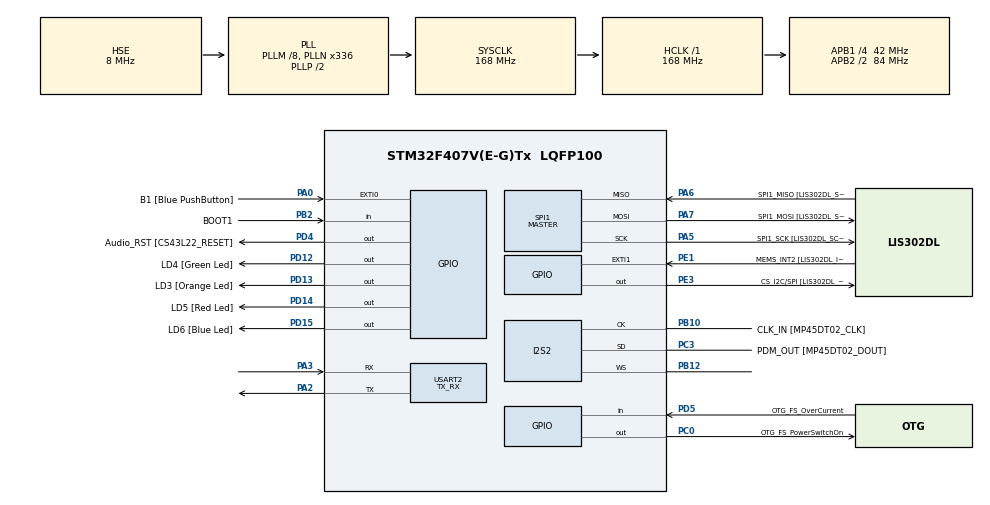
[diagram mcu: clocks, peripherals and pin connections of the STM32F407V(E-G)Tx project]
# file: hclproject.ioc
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Dma.Request0=SPI2_RX
Dma.Request1=USART2_TX
Dma.SPI2_RX.0.Direction=DMA_PERIPH_TO_MEMORY
Dma.SPI2_RX.0.FIFOMode=DMA_FIFOMODE_DISABLE
Dma.SPI2_RX.0.Instance=DMA1_Stream3
Dma.SPI2_RX.0.MemDataAlignment=DMA_MDATAALIGN_WORD
Dma.SPI2_RX.0.MemInc=DMA_MINC_ENABLE
Dma.SPI2_RX.0.Mode=DMA_CIRCULAR
Dma.SPI2_RX.0.PeriphDataAlignment=DMA_PDATAALIGN_WORD
Dma.SPI2_RX.0.PeriphInc=DMA_PINC_DISABLE
Dma.SPI2_RX.0.Priority=DMA_PRIORITY_HIGH
Dma.USART2_TX.1.Direction=DMA_MEMORY_TO_PERIPH
Dma.USART2_TX.1.FIFOMode=DMA_FIFOMODE_DISABLE
Dma.USART2_TX.1.Instance=DMA1_Stream6
Dma.USART2_TX.1.MemDataAlignment=DMA_MDATAALIGN_BYTE
Dma.USART2_TX.1.MemInc=DMA_MINC_ENABLE
Dma.USART2_TX.1.Mode=DMA_CIRCULAR
Dma.USART2_TX.1.PeriphDataAlignment=DMA_PDATAALIGN_BYTE
Dma.USART2_TX.1.PeriphInc=DMA_PINC_DISABLE
Dma.USART2_TX.1.Priority=DMA_PRIORITY_MEDIUM
I2S2.AudioFreq=I2S_AUDIOFREQ_16K
I2S2.DataFormat=I2S_DATAFORMAT_24B
I2S2.ErrorAudioFreq=-0.26 %
I2S2.FullDuplexMode=I2S_FULLDUPLEXMODE_DISABLE
I2S2.Instance=SPI$Index
I2S2.Mode=I2S_MODE_MASTER_RX
I2S2.RealAudioFreq=15.957 KHz
I2S2.VirtualMode=I2S_MODE_MASTER
Mcu.Family=STM32F4
Mcu.Name=STM32F407V(E-G)Tx
Mcu.Package=LQFP100
NVIC.DMA1_Stream3_IRQn=true\:0\:0\:false\:false\:true\:false\:true\:true
NVIC.DMA1_Stream6_IRQn=true\:0\:0\:false\:false\:true\:false\:true\:true
NVIC.PriorityGroup=NVIC_PRIORITYGROUP_0
PA0-WKUP.GPIO_Label=B1 [Blue PushButton]
PA0-WKUP.GPIO_ModeDefaultEXTI=GPIO_MODE_EVT_RISING
PA0-WKUP.GPIO_PuPd=GPIO_NOPULL
PA0-WKUP.Signal=GPXTI0
PA10.GPIO_Label=OTG_FS_ID
PA10.GPIO_Mode=GPIO_MODE_AF_PP
PA10.GPIO_PuPd=GPIO_NOPULL
PA10.GPIO_Speed=GPIO_SPEED_FREQ_LOW
PA10.Signal=USB_OTG_FS_ID
PA11.GPIO_Label=OTG_FS_DM
PA11.GPIO_Mode=GPIO_MODE_AF_PP
PA11.GPIO_PuPd=GPIO_NOPULL
PA11.GPIO_Speed=GPIO_SPEED_FREQ_LOW
PA11.Signal=USB_OTG_FS_DM
PA12.GPIO_Label=OTG_FS_DP
PA12.GPIO_Mode=GPIO_MODE_AF_PP
PA12.GPIO_PuPd=GPIO_NOPULL
PA12.GPIO_Speed=GPIO_SPEED_FREQ_LOW
PA12.Signal=USB_OTG_FS_DP
PA13.GPIO_Label=SWDIO
PA13.Mode=Serial_Wire
PA13.Signal=SYS_JTMS-SWDIO
PA14.GPIO_Label=SWCLK
PA14.Mode=Serial_Wire
PA14.Signal=SYS_JTCK-SWCLK
PA2.Mode=Asynchronous
PA2.Signal=USART2_TX
PA3.Mode=Asynchronous
PA3.Signal=USART2_RX
PA4.GPIO_Label=I2S3_WS [CS43L22_LRCK]
PA4.GPIO_Mode=GPIO_MODE_AF_PP
PA4.GPIO_PuPd=GPIO_NOPULL
PA4.GPIO_Speed=GPIO_SPEED_FREQ_LOW
PA4.Signal=I2S3_WS
PA5.GPIO_Label=SPI1_SCK [LIS302DL_SCL/SPC]
PA5.GPIO_Mode=GPIO_MODE_AF_PP
PA5.GPIO_PuPd=GPIO_NOPULL
PA5.GPIO_Speed=GPIO_SPEED_FREQ_LOW
PA5.Mode=Full_Duplex_Master
PA5.Signal=SPI1_SCK
PA6.GPIO_Label=SPI1_MISO [LIS302DL_SDO]
PA6.GPIO_Mode=GPIO_MODE_AF_PP
PA6.GPIO_PuPd=GPIO_NOPULL
PA6.GPIO_Speed=GPIO_SPEED_FREQ_LOW
PA6.Mode=Full_Duplex_Master
PA6.Signal=SPI1_MISO
PA7.GPIO_Label=SPI1_MOSI [LIS302DL_SDA/SDI/SDO]
PA7.GPIO_Mode=GPIO_MODE_AF_PP
PA7.GPIO_PuPd=GPIO_NOPULL
PA7.GPIO_Speed=GPIO_SPEED_FREQ_LOW
PA7.Mode=Full_Duplex_Master
PA7.Signal=SPI1_MOSI
PA9.GPIO_Label=VBUS_FS
PA9.GPIO_Mode=GPIO_MODE_INPUT
PA9.GPIO_PuPd=GPIO_NOPULL
PA9.Signal=USB_OTG_FS_VBUS
PB10.GPIO_Label=CLK_IN [MP45DT02_CLK]
PB10.GPIO_Mode=GPIO_MODE_AF_PP
PB10.GPIO_PuPd=GPIO_NOPULL
PB10.GPIO_Speed=GPIO_SPEED_FREQ_LOW
PB10.Mode=Half_Duplex_Master
PB10.Signal=I2S2_CK
PB12.Mode=Half_Duplex_Master
PB12.Signal=I2S2_WS
PB2.GPIO_Label=BOOT1
PB2.GPIO_Mode=GPIO_MODE_INPUT
PB2.GPIO_PuPd=GPIO_NOPULL
PB2.Signal=GPIO_Input
PB3.GPIO_Label=SWO
PB3.Signal=SYS_JTDO-SWO
PB6.GPIO_Label=Audio_SCL [CS43L22_SCL]
PB6.GPIO_Mode=GPIO_MODE_AF_OD
PB6.GPIO_Pu=GPIO_PULLUP
PB6.GPIO_PuPd=GPIO_NOPULL
PB6.GPIO_Speed=GPIO_SPEED_FREQ_LOW
PB6.Signal=I2C1_SCL
PB9.GPIO_Label=Audio_SDA [CS43L22_SDA]
PB9.GPIO_Mode=GPIO_MODE_AF_OD
PB9.GPIO_Pu=GPIO_PULLUP
PB9.GPIO_PuPd=GPIO_NOPULL
PB9.GPIO_Speed=GPIO_SPEED_FREQ_LOW
PB9.Signal=I2C1_SDA
PC0.GPIO_Label=OTG_FS_PowerSwitchOn
PC0.GPIO_PuPd=GPIO_NOPULL
PC0.GPIO_Speed=GPIO_SPEED_FREQ_LOW
PC0.PinState=GPIO_PIN_SET
PC0.Signal=GPIO_Output
PC10.GPIO_Label=I2S3_SCK [CS43L22_SCLK]
PC10.GPIO_Mode=GPIO_MODE_AF_PP
PC10.GPIO_PuPd=GPIO_NOPULL
PC10.GPIO_Speed=GPIO_SPEED_FREQ_LOW
PC10.Signal=I2S3_CK
PC12.GPIO_Label=I2S3_SD [CS43L22_SDIN]
PC12.GPIO_Mode=GPIO_MODE_AF_PP
PC12.GPIO_PuPd=GPIO_NOPULL
PC12.GPIO_Speed=GPIO_SPEED_FREQ_LOW
PC12.Signal=I2S3_SD
PC14-OSC32_IN.GPIO_Label=PC14-OSC32_IN
PC14-OSC32_IN.Mode=LSE-External-Oscillator
PC14-OSC32_IN.Signal=RCC_OSC32_IN
PC15-OSC32_OUT.GPIO_Label=PC15-OSC32_OUT
PC15-OSC32_OUT.Mode=LSE-External-Oscillator
PC15-OSC32_OUT.Signal=RCC_OSC32_OUT
PC3.GPIO_Label=PDM_OUT [MP45DT02_DOUT]
PC3.GPIO_Mode=GPIO_MODE_AF_PP
PC3.GPIO_PuPd=GPIO_NOPULL
PC3.GPIO_Speed=GPIO_SPEED_FREQ_LOW
PC3.Mode=Half_Duplex_Master
PC3.Signal=I2S2_SD
PC7.GPIO_Label=I2S3_MCK [CS43L22_MCLK]
PC7.GPIO_Mode=GPIO_MODE_AF_PP
PC7.GPIO_PuPd=GPIO_NOPULL
PC7.GPIO_Speed=GPIO_SPEED_FREQ_LOW
PC7.Signal=I2S3_MCK
PD12.GPIO_Label=LD4 [Green Led]
PD12.GPIO_PuPd=GPIO_NOPULL
PD12.GPIO_Speed=GPIO_SPEED_FREQ_LOW
PD12.Signal=GPIO_Output
PD13.GPIO_Label=LD3 [Orange Led]
PD13.GPIO_PuPd=GPIO_NOPULL
PD13.GPIO_Speed=GPIO_SPEED_FREQ_LOW
PD13.Signal=GPIO_Output
PD14.GPIO_Label=LD5 [Red Led]
PD14.GPIO_PuPd=GPIO_NOPULL
PD14.GPIO_Speed=GPIO_SPEED_FREQ_LOW
PD14.Signal=GPIO_Output
PD15.GPIO_Label=LD6 [Blue Led]
PD15.GPIO_PuPd=GPIO_NOPULL
PD15.GPIO_Speed=GPIO_SPEED_FREQ_LOW
PD15.Signal=GPIO_Output
PD4.GPIO_Label=Audio_RST [CS43L22_RESET]
PD4.GPIO_PuPd=GPIO_NOPULL
PD4.GPIO_Speed=GPIO_SPEED_FREQ_LOW
PD4.Signal=GPIO_Output
PD5.GPIO_Label=OTG_FS_OverCurrent
PD5.GPIO_Mode=GPIO_MODE_INPUT
PD5.GPIO_PuPd=GPIO_NOPULL
PD5.Signal=GPIO_Input
PE1.GPIO_Label=MEMS_INT2 [LIS302DL_INT2]
PE1.GPIO_ModeDefaultEXTI=GPIO_MODE_EVT_RISING
PE1.GPIO_PuPd=GPIO_NOPULL
PE1.Signal=GPXTI1
PE3.GPIO_Label=CS_I2C/SPI [LIS302DL_CS_I2C/SPI]
PE3.GPIO_PuPd=GPIO_NOPULL
PE3.GPIO_Speed=GPIO_SPEED_FREQ_LOW
PE3.Signal=GPIO_Output
PH0-OSC_IN.GPIO_Label=PH0-OSC_IN
PH0-OSC_IN.Mode=HSE-External-Oscillator
PH0-OSC_IN.Signal=RCC_OSC_IN
PH1-OSC_OUT.GPIO_Label=PH1-OSC_OUT
PH1-OSC_OUT.Mode=HSE-External-Oscillator
PH1-OSC_OUT.Signal=RCC_OSC_OUT
ProjectManager.HeapSize=0x200
ProjectManager.StackSize=0x400
ProjectManager.TargetToolchain=STM32CubeIDE
RCC.48MHZClocksFreq_Value=48000000
RCC.AHBFreq_Value=168000000
RCC.APB1CLKDivider=RCC_HCLK_DIV4
RCC.APB1Freq_Value=42000000
RCC.APB1TimFreq_Value=84000000
RCC.APB2CLKDivider=RCC_HCLK_DIV2
RCC.APB2Freq_Value=84000000
RCC.APB2TimFreq_Value=168000000
RCC.CortexFreq_Value=168000000
RCC.HCLKFreq_Value=168000000
RCC.HSE_VALUE=8000000
RCC.HSI_VALUE=16000000
RCC.PLLM=8
RCC.PLLN=336
RCC.PLLQ=7
RCC.PLLSourceVirtual=RCC_PLLSOURCE_HSE
RCC.SYSCLKFreq_VALUE=168000000
RCC.SYSCLKSource=RCC_SYSCLKSOURCE_PLLCLK
RCC.VCOOutputFreq_Value=336000000
SPI1.BaudRatePrescaler-Full_Duplex_Master=SPI_BAUDRATEPRESCALER_2
SPI1.CalculateBaudRate-Full_Duplex_Master=42.0 MBits/s
SPI1.Direction=SPI_DIRECTION_2LINES
SPI1.Mode=SPI_MODE_MASTER
SPI1.Mode-Full_Duplex_Master=SPI_MODE_MASTER
SPI1.VirtualType=VM_MASTER
USART2.Mode=MODE_TX_RX
USART2.VirtualMode=VM_ASYNC
board=STM32F407G-DISC1

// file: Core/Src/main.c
#include "main.h"
#include "dma.h"
#include "i2s.h"
#include "spi.h"
#include "usart.h"
#include "gpio.h"
#include "arm_math.h"
#include <stdio.h>
#include <string.h>

#define BUFFER_SIZE 1024
#define FFT_SIZE 1024
#define GAIN 2500
#define FILTER_TAP_NUM 32
#define FFT_SCALE_FACTOR (2.0f/FFT_SIZE)

#define MIN_FREQ 20
#define MAX_FREQ 8000
#define SAMPLING_RATE 8000.0f

//Calibration
#define CALIBRATION_TIME 10000
static float32_t calibration_sum = 0.0f;
static uint32_t calibration_samples = 0;
int calibrated = 0;
float32_t prev_average_magnitude = 0;

char temp[64];
// Add these at the top
#define VOCAL_START_BIN 7   // 50Hz (7*7.8Hz = 54.6Hz)
#define VOCAL_END_BIN 39    // 300Hz (39*7.8Hz = 304.2Hz)
#define BIN_GROUP_SIZE 3
#define SPIKE_THRESHOLD 4   // Adjust based on the room noise
uint8_t spike_counter = 0;
#define NO_OF_SPIKES 3

//Alert transmission
volatile uint8_t alert_pending = 0;
#define UART_FLUSH_DELAY 20

int32_t i2s_rx_buffer[2][BUFFER_SIZE];
static float32_t fft_input[FFT_SIZE] __attribute__((aligned(4)));
static float32_t fft_output[FFT_SIZE] __attribute__((aligned(4)));
static float32_t mag_output[FFT_SIZE / 2] __attribute__((aligned(4)));

volatile uint8_t active_buffer = 0;
volatile uint8_t fft_ready = 0;

// Optimized bandpass filter coefficients
const float32_t bp_filter[FILTER_TAP_NUM] = {
    -0.001747f, -0.003912f, -0.004215f, 0.000000f, 0.009645f,
    0.017835f, 0.011983f, -0.015430f, -0.042257f, -0.042351f,
    0.000000f, 0.063517f, 0.098550f, 0.063517f, 0.000000f,
    -0.042351f, -0.042257f, -0.015430f, 0.011983f, 0.017835f,
    0.009645f, 0.000000f, -0.004215f, -0.003912f, -0.001747f
};

float32_t hanning_window[FFT_SIZE];
float32_t fir_state[FFT_SIZE + FILTER_TAP_NUM - 1];
arm_rfft_fast_instance_f32 fft_instance;
arm_fir_instance_f32 fir_instance;

void SystemClock_Config(void);

// DMA Callbacks
void HAL_I2S_RxHalfCpltCallback(I2S_HandleTypeDef *hi2s) {
    active_buffer = 0;
    fft_ready = 1;
}

void HAL_I2S_RxCpltCallback(I2S_HandleTypeDef *hi2s) {
    active_buffer = 1;
    fft_ready = 1;
}

void init_filters() {
    arm_fir_init_f32(&fir_instance, FILTER_TAP_NUM, bp_filter, fir_state, FFT_SIZE);
}

void bandpass_filter(float32_t *input, float32_t *output) {
    arm_fir_f32(&fir_instance, input, output, FFT_SIZE);
}

void send_frequency_data(float* mag_output) {
    const int start_bin = (int)(MIN_FREQ * FFT_SIZE / SAMPLING_RATE);
    const int end_bin = (int)(MAX_FREQ * FFT_SIZE / SAMPLING_RATE);
    char buffer[1024];
    int offset = 0;

    // Skip bin 0 if it's below the desired frequency range
    for (int i = (start_bin > 0 ? start_bin : 1); i <= end_bin; i++) {
        float freq = i * (SAMPLING_RATE / FFT_SIZE);  // 125Hz per bin
        float mag = mag_output[i];
        offset += snprintf(buffer + offset, sizeof(buffer) - offset,
                           "%.1fhz:%.2f ", freq, mag);
        if (offset >= sizeof(buffer) - 20) break; // Prevent overflow
    }

    if (offset > 0) {
        buffer[offset-1] = '\r'; // Replace last space
        buffer[offset] = '\n';
        HAL_UART_Transmit(&huart2, (uint8_t*)buffer, offset+1, 100);
    }
}

int main(void) {
    HAL_Init();
    SystemClock_Config();
    MX_GPIO_Init();
    MX_DMA_Init();
    MX_SPI1_Init();
    MX_I2S2_Init();
    MX_USART2_UART_Init();
    __HAL_UART_FLUSH_DRREGISTER(&huart2);

    // FFT initialization
    if (arm_rfft_fast_init_1024_f32(&fft_instance) != ARM_MATH_SUCCESS) {
        char debug_buf[50];
        sprintf(debug_buf, "FFT Init Failed!\r\n");
        HAL_UART_Transmit(&huart2, (uint8_t*)debug_buf, strlen(debug_buf), 100);
        while(1);
    }
    init_filters();
    HAL_I2S_Receive_DMA(&hi2s2, (uint16_t*)i2s_rx_buffer, BUFFER_SIZE * 2);

    while(1) {
        if(fft_ready) {
            fft_ready = 0;
            int32_t *processing_buffer = i2s_rx_buffer[active_buffer];

            // DC offset calculation
            int32_t dc_offset = 0;
            for(int i=0; i<FFT_SIZE; i++) {
                dc_offset += (processing_buffer[i] << 8) >> 8;
            }
            dc_offset /= FFT_SIZE;

            // Convert to float
            for(int i=0; i<FFT_SIZE; i++) {
                int32_t pcm_data = ((processing_buffer[i] << 8) >> 8) - dc_offset;
                pcm_data *= GAIN;
                fft_input[i] = (float32_t)pcm_data / 8388608.0f;
            }

            // Filtering and windowing
            float32_t filtered_output[FFT_SIZE];
            bandpass_filter(fft_input, filtered_output);
            arm_hanning_f32(hanning_window, FFT_SIZE);
            for(int i=0; i<FFT_SIZE; i++) {
                fft_input[i] = filtered_output[i] * hanning_window[i];
            }

            // FFT processing
            arm_rfft_fast_f32(&fft_instance, fft_input, fft_output, 0);
            arm_cmplx_mag_f32(fft_output, mag_output, FFT_SIZE/2);

            for(int i=0; i<FFT_SIZE/2; i++) {
                mag_output[i] *= FFT_SCALE_FACTOR * GAIN;
            }

            send_frequency_data(mag_output);

            if(!calibrated) {
                if(HAL_GetTick() <= CALIBRATION_TIME) {
                    // Store baseline for each bin group
                    for(int i=VOCAL_START_BIN; i<VOCAL_END_BIN; i+=BIN_GROUP_SIZE) {
                        float group_sum = 0;
                        for(int j=0; j<BIN_GROUP_SIZE; j++){
                            if(i+j >= FFT_SIZE/2) break;
                            group_sum += mag_output[i+j];
                        }
                        calibration_sum += group_sum/BIN_GROUP_SIZE;
                        calibration_samples++;
                    }
                }
                else {
                    // Calculate average per bin group
                    prev_average_magnitude = calibration_sum / calibration_samples;
                    calibrated = 1;

                    char cal_msg[64];
                    snprintf(cal_msg, sizeof(cal_msg), "CALIBRATED:%.2f\r\n", prev_average_magnitude);

                    HAL_UART_Transmit(&huart2, (uint8_t*)cal_msg, strlen(cal_msg), 100);
                }
            }
            else {
                float current_spike_sum = 0;
                uint8_t spiked_groups = 0;

                // Check each bin group in vocal range
                for(int i=VOCAL_START_BIN; i<VOCAL_END_BIN; i+=BIN_GROUP_SIZE) {
                    float group_sum = 0;

                    // Calculate current group average
                    for(int j=0; j<BIN_GROUP_SIZE; j++){
                        if(i+j >= FFT_SIZE/2) break;
                        group_sum += mag_output[i+j];
                    }
                    float group_avg = group_sum/BIN_GROUP_SIZE;

                    // Detect spikes in this bin group
                    if(group_avg > (prev_average_magnitude * SPIKE_THRESHOLD)) {
                        spiked_groups++;
                        current_spike_sum += group_avg;
                    }
                }

                // If at least 2 bin groups spiked
                if(spiked_groups >= 2) {
                    spike_counter++;

                    // Require 3 consecutive detections
                    if(spike_counter >= NO_OF_SPIKES) {
                        float current_avg = current_spike_sum/spiked_groups;
                        char alert_msg[64];
                        snprintf(alert_msg, sizeof(alert_msg),"ALERT:%.2f/%.2f\r\n",
                                current_avg, prev_average_magnitude);
                        HAL_UART_Transmit(&huart2, (uint8_t*)alert_msg, strlen(alert_msg), 100);
                        spike_counter = 0;
                    }
                }
                else {
                    // Decay spike counter
                    spike_counter = spike_counter > 0 ? spike_counter-1 : 0;
                }

                if(spike_counter == 0) {
                    prev_average_magnitude = 0.95f * prev_average_magnitude + 0.05f * current_spike_sum;
                }
            }

        }
        HAL_Delay(1);
    }
}
void SystemClock_Config(void)
{
  RCC_OscInitTypeDef RCC_OscInitStruct = {0};
  RCC_ClkInitTypeDef RCC_ClkInitStruct = {0};

  /** Configure the main internal regulator output voltage
  */
  __HAL_RCC_PWR_CLK_ENABLE();
  __HAL_PWR_VOLTAGESCALING_CONFIG(PWR_REGULATOR_VOLTAGE_SCALE1);

  /** Initializes the RCC Oscillators according to the specified parameters
  * in the RCC_OscInitTypeDef structure.
  */
  RCC_OscInitStruct.OscillatorType = RCC_OSCILLATORTYPE_HSE;
  RCC_OscInitStruct.HSEState = RCC_HSE_ON;
  RCC_OscInitStruct.PLL.PLLState = RCC_PLL_ON;
  RCC_OscInitStruct.PLL.PLLSource = RCC_PLLSOURCE_HSE;
  RCC_OscInitStruct.PLL.PLLM = 8;
  RCC_OscInitStruct.PLL.PLLN = 336;
  RCC_OscInitStruct.PLL.PLLP = RCC_PLLP_DIV2;
  RCC_OscInitStruct.PLL.PLLQ = 7;
  if (HAL_RCC_OscConfig(&RCC_OscInitStruct) != HAL_OK)
  {
    Error_Handler();
  }

  /** Initializes the CPU, AHB and APB buses clocks
  */
  RCC_ClkInitStruct.ClockType = RCC_CLOCKTYPE_HCLK|RCC_CLOCKTYPE_SYSCLK
                              |RCC_CLOCKTYPE_PCLK1|RCC_CLOCKTYPE_PCLK2;
  RCC_ClkInitStruct.SYSCLKSource = RCC_SYSCLKSOURCE_PLLCLK;
  RCC_ClkInitStruct.AHBCLKDivider = RCC_SYSCLK_DIV1;
  RCC_ClkInitStruct.APB1CLKDivider = RCC_HCLK_DIV4;
  RCC_ClkInitStruct.APB2CLKDivider = RCC_HCLK_DIV2;

  if (HAL_RCC_ClockConfig(&RCC_ClkInitStruct, FLASH_LATENCY_5) != HAL_OK)
  {
    Error_Handler();
  }
}

void HAL_UART_TxCpltCallback(UART_HandleTypeDef *huart) {
    __HAL_UART_FLUSH_DRREGISTER(huart);
}
void Error_Handler(void)
{
  /* USER CODE BEGIN Error_Handler_Debug */
  /* User can add his own implementation to report the HAL error return state */
  __disable_irq();
  while (1)
  {
      HAL_UART_Transmit(&huart2, (uint8_t*)"FATAL_ERROR\r\n", 13, 100);
      HAL_Delay(1000);
  }
  /* USER CODE END Error_Handler_Debug */
}
